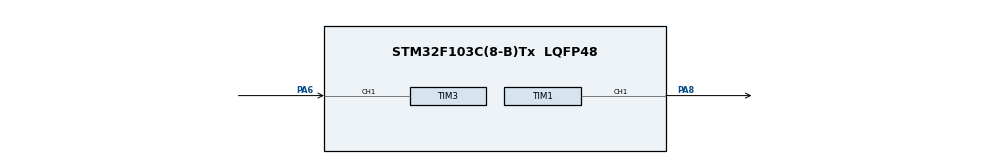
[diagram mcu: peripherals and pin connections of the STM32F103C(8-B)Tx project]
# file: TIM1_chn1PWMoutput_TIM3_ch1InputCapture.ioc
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Dma.Request0=TIM1_CH1
Dma.TIM1_CH1.0.Direction=DMA_MEMORY_TO_PERIPH
Dma.TIM1_CH1.0.Instance=DMA1_Channel2
Dma.TIM1_CH1.0.MemDataAlignment=DMA_MDATAALIGN_WORD
Dma.TIM1_CH1.0.MemInc=DMA_MINC_ENABLE
Dma.TIM1_CH1.0.Mode=DMA_CIRCULAR
Dma.TIM1_CH1.0.PeriphDataAlignment=DMA_PDATAALIGN_HALFWORD
Dma.TIM1_CH1.0.PeriphInc=DMA_PINC_DISABLE
Dma.TIM1_CH1.0.Priority=DMA_PRIORITY_HIGH
Mcu.Family=STM32F1
Mcu.Name=STM32F103C(8-B)Tx
Mcu.Package=LQFP48
NVIC.DMA1_Channel2_IRQn=true\:0\:0\:false\:false\:true
NVIC.PriorityGroup=NVIC_PRIORITYGROUP_4
NVIC.TIM3_IRQn=true\:0\:0\:false\:false\:true
PA6.GPIO_PuPd=GPIO_NOPULL
PA6.Signal=S_TIM3_CH1
PA8.GPIO_Speed=GPIO_SPEED_FREQ_HIGH
PA8.Signal=S_TIM1_CH1
PD0-OSC_IN.Mode=HSE-External-Oscillator
PD0-OSC_IN.Signal=RCC_OSC_IN
PD1-OSC_OUT.Mode=HSE-External-Oscillator
PD1-OSC_OUT.Signal=RCC_OSC_OUT
ProjectManager.HeapSize=0x200
ProjectManager.StackSize=0x400
ProjectManager.TargetToolchain=SW4STM32
RCC.APB1Freq_Value=8000000
RCC.APB2Freq_Value=8000000
SH.S_TIM1_CH1.0=TIM1_CH1,PWM Generation1 CH1
SH.S_TIM3_CH1.0=TIM3_CH1,Input_Capture1_from_TI1
TIM1.Channel-PWM\ Generation1\ CH1=TIM_CHANNEL_1
TIM1.TIM_MasterOutputTrigger=TIM_TRGO_OC1
TIM3.Channel-Input_Capture1_from_TI1=TIM_CHANNEL_1
TIM3.ICFilter_CH1=0
TIM3.Period=0
VP_TIM3_VS_ClockSourceINT.Mode=Internal
board=TIM1_chn1PWMoutput_TIM3_ch1InputCapture

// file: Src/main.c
/**
  ******************************************************************************
  * File Name          : main.c
  * Description        : Main program body
  ******************************************************************************
  ** This notice applies to any and all portions of this file
  * that are not between comment pairs USER CODE BEGIN and
  * USER CODE END. Other portions of this file, whether
  * inserted by the user or by software development tools
  * are owned by their respective copyright owners.
  *
  * COPYRIGHT(c) 2017 STMicroelectronics
  *
  * Redistribution and use in source and binary forms, with or without modification,
  * are permitted provided that the following conditions are met:
  *   1. Redistributions of source code must retain the above copyright notice,
  *      this list of conditions and the following disclaimer.
  *   2. Redistributions in binary form must reproduce the above copyright notice,
  *      this list of conditions and the following disclaimer in the documentation
  *      and/or other materials provided with the distribution.
  *   3. Neither the name of STMicroelectronics nor the names of its contributors
  *      may be used to endorse or promote products derived from this software
  *      without specific prior written permission.
  *
  * THIS SOFTWARE IS PROVIDED BY THE COPYRIGHT HOLDERS AND CONTRIBUTORS "AS IS"
  * AND ANY EXPRESS OR IMPLIED WARRANTIES, INCLUDING, BUT NOT LIMITED TO, THE
  * IMPLIED WARRANTIES OF MERCHANTABILITY AND FITNESS FOR A PARTICULAR PURPOSE ARE
  * DISCLAIMED. IN NO EVENT SHALL THE COPYRIGHT HOLDER OR CONTRIBUTORS BE LIABLE
  * FOR ANY DIRECT, INDIRECT, INCIDENTAL, SPECIAL, EXEMPLARY, OR CONSEQUENTIAL
  * DAMAGES (INCLUDING, BUT NOT LIMITED TO, PROCUREMENT OF SUBSTITUTE GOODS OR
  * SERVICES; LOSS OF USE, DATA, OR PROFITS; OR BUSINESS INTERRUPTION) HOWEVER
  * CAUSED AND ON ANY THEORY OF LIABILITY, WHETHER IN CONTRACT, STRICT LIABILITY,
  * OR TORT (INCLUDING NEGLIGENCE OR OTHERWISE) ARISING IN ANY WAY OUT OF THE USE
  * OF THIS SOFTWARE, EVEN IF ADVISED OF THE POSSIBILITY OF SUCH DAMAGE.
  *
  ******************************************************************************
  */
#include "main.h"
#include "stm32f1xx_hal.h"

TIM_HandleTypeDef htim1;
TIM_HandleTypeDef htim3;
DMA_HandleTypeDef hdma_tim1_ch1;

/* USER CODE BEGIN PV */
/* Private variables ---------------------------------------------------------*/
/* Timer handler declaration */
TIM_HandleTypeDef TimHandle;

/* Timer Output Compare Configuration Structure declaration */
TIM_OC_InitTypeDef sConfig;

/* Capture Compare buffer */
uint32_t aCCValue_Buffer[3] = { 0, 0, 0 };

/* Timer Period*/
uint32_t uhTimerPeriod = 0;

/* Timer Input Capture Configuration Structure declaration */
TIM_IC_InitTypeDef sICConfig;

/* Captured Values */
uint32_t uwIC2Value1 = 0;
uint32_t uwIC2Value2 = 0;
uint32_t uwDiffCapture = 0;

/* Capture index */
uint16_t uhCaptureIndex = 0;

/* Frequency Value */
uint32_t uwFrequency = 0;

/* USER CODE END PV */

void SystemClock_Config(void);
static void MX_GPIO_Init(void);
static void MX_DMA_Init(void);
static void MX_TIM3_Init(void);
static void MX_TIM1_Init(void);
void HAL_TIM_MspPostInit(TIM_HandleTypeDef *htim);

/* USER CODE BEGIN PFP */
/* Private function prototypes -----------------------------------------------*/

/* USER CODE END PFP */

/* USER CODE BEGIN 0 */
void HAL_TIM_IC_CaptureCallback(TIM_HandleTypeDef *htim)
{
  if (htim->Channel == HAL_TIM_ACTIVE_CHANNEL_1)
  {
    if(uhCaptureIndex == 0)
    {
      /* Get the 1st Input Capture value */
      uwIC2Value1 = HAL_TIM_ReadCapturedValue(htim, TIM_CHANNEL_1);
      uhCaptureIndex = 1;
    }
    else if(uhCaptureIndex == 1)
    {
      /* Get the 2nd Input Capture value */
      uwIC2Value2 = HAL_TIM_ReadCapturedValue(htim, TIM_CHANNEL_1);

      /* Capture computation */
      if (uwIC2Value2 > uwIC2Value1)
      {
        uwDiffCapture = (uwIC2Value2 - uwIC2Value1);
      }
      else  /* (uwIC2Value2 <= uwIC2Value1) */
      {
        uwDiffCapture = ((0xFFFF - uwIC2Value1) + uwIC2Value2);
      }

      /* Frequency computation: for this example TIMx (TIM1) is clocked by
         2xAPB2Clk */
      uwFrequency = (2*HAL_RCC_GetPCLK2Freq()) / uwDiffCapture;
      uhCaptureIndex = 0;
    }
  }
}
/* USER CODE END 0 */

int main(void)
{

  /* MCU Configuration----------------------------------------------------------*/

  /* Reset of all peripherals, Initializes the Flash interface and the Systick. */
  HAL_Init();

  /* Configure the system clock */
  SystemClock_Config();

  /* Initialize all configured peripherals */
  MX_GPIO_Init();
  MX_DMA_Init();
  MX_TIM3_Init();
  MX_TIM1_Init();

  /* USER CODE BEGIN 2 */
	uhTimerPeriod = (uint32_t) ((SystemCoreClock / 10000) - 1);
	aCCValue_Buffer[0] =
			(uint32_t) (((uint32_t) 25 * (uhTimerPeriod - 1)) / 100);
	aCCValue_Buffer[1] =
			(uint32_t) (((uint32_t) 25 * (uhTimerPeriod - 1)) / 100);
	aCCValue_Buffer[2] =
			(uint32_t) (((uint32_t) 25 * (uhTimerPeriod - 1)) / 100);

	TimHandle.Instance = TIM1;
	TimHandle.Init.Period = uhTimerPeriod;
	TimHandle.Init.RepetitionCounter = 3;
	TimHandle.Init.Prescaler = 0;
	TimHandle.Init.ClockDivision = 0;
	TimHandle.Init.CounterMode = TIM_COUNTERMODE_UP;
	if (HAL_TIM_PWM_Init(&TimHandle) != HAL_OK) {
		/* Initialization Error */
		Error_Handler();
	}

	/*##-2- Configure the PWM channel 3 ########################################*/
	sConfig.OCMode = TIM_OCMODE_PWM1;
	sConfig.OCPolarity = TIM_OCPOLARITY_HIGH;
	sConfig.Pulse = aCCValue_Buffer[0];
	if (HAL_TIM_PWM_ConfigChannel(&TimHandle, &sConfig, TIM_CHANNEL_1)
			!= HAL_OK) {
		/* Configuration Error */
		Error_Handler();
	}

	/*##-3- Start PWM signal generation in DMA mode ############################*/
	if (HAL_TIM_PWM_Start_DMA(&TimHandle, TIM_CHANNEL_1, aCCValue_Buffer, 3)
			!= HAL_OK) {
		/* Starting PWM generation Error */
		Error_Handler();
	}
	TimHandle.Instance = TIM3;

	TimHandle.Init.Period = 0xFFFF;
	TimHandle.Init.Prescaler = 0;
	TimHandle.Init.ClockDivision = 0;
	TimHandle.Init.CounterMode = TIM_COUNTERMODE_UP;
	if (HAL_TIM_IC_Init(&TimHandle) != HAL_OK) {
		/* Initialization Error */
		Error_Handler();
	}

	sICConfig.ICPolarity = TIM_ICPOLARITY_RISING;
	sICConfig.ICSelection = TIM_ICSELECTION_DIRECTTI;
	sICConfig.ICPrescaler = TIM_ICPSC_DIV1;
	sICConfig.ICFilter = 0;
	if (HAL_TIM_IC_ConfigChannel(&TimHandle, &sICConfig, TIM_CHANNEL_1)
			!= HAL_OK) {
		/* Configuration Error */
		Error_Handler();
	}

	/*##-3- Start the Input Capture in interrupt mode ##########################*/
	if (HAL_TIM_IC_Start_IT(&TimHandle, TIM_CHANNEL_1) != HAL_OK) {
		/* Starting Error */
		Error_Handler();
	}
  /* USER CODE END 2 */
	int count = 0;
  /* Infinite loop */
	while (1) {

  /* USER CODE BEGIN 3 */
		if(count != 0)
			count  = 0;
		else
			count = 1;
	}
  /* USER CODE END 3 */

}

/** System Clock Configuration
*/
void SystemClock_Config(void)
{

  RCC_OscInitTypeDef RCC_OscInitStruct;
  RCC_ClkInitTypeDef RCC_ClkInitStruct;

    /**Initializes the CPU, AHB and APB busses clocks
    */
  RCC_OscInitStruct.OscillatorType = RCC_OSCILLATORTYPE_HSI;
  RCC_OscInitStruct.HSIState = RCC_HSI_ON;
  RCC_OscInitStruct.HSICalibrationValue = 16;
  RCC_OscInitStruct.PLL.PLLState = RCC_PLL_NONE;
  if (HAL_RCC_OscConfig(&RCC_OscInitStruct) != HAL_OK)
  {
    _Error_Handler(__FILE__, __LINE__);
  }

    /**Initializes the CPU, AHB and APB busses clocks
    */
  RCC_ClkInitStruct.ClockType = RCC_CLOCKTYPE_HCLK|RCC_CLOCKTYPE_SYSCLK
                              |RCC_CLOCKTYPE_PCLK1|RCC_CLOCKTYPE_PCLK2;
  RCC_ClkInitStruct.SYSCLKSource = RCC_SYSCLKSOURCE_HSI;
  RCC_ClkInitStruct.AHBCLKDivider = RCC_SYSCLK_DIV1;
  RCC_ClkInitStruct.APB1CLKDivider = RCC_HCLK_DIV1;
  RCC_ClkInitStruct.APB2CLKDivider = RCC_HCLK_DIV1;

  if (HAL_RCC_ClockConfig(&RCC_ClkInitStruct, FLASH_LATENCY_0) != HAL_OK)
  {
    _Error_Handler(__FILE__, __LINE__);
  }

    /**Configure the Systick interrupt time
    */
  HAL_SYSTICK_Config(HAL_RCC_GetHCLKFreq()/1000);

    /**Configure the Systick
    */
  HAL_SYSTICK_CLKSourceConfig(SYSTICK_CLKSOURCE_HCLK);

  /* SysTick_IRQn interrupt configuration */
  HAL_NVIC_SetPriority(SysTick_IRQn, 0, 0);
}

/* TIM1 init function */
static void MX_TIM1_Init(void)
{

  TIM_MasterConfigTypeDef sMasterConfig;
  TIM_OC_InitTypeDef sConfigOC;
  TIM_BreakDeadTimeConfigTypeDef sBreakDeadTimeConfig;

  htim1.Instance = TIM1;
  htim1.Init.Prescaler = 0;
  htim1.Init.CounterMode = TIM_COUNTERMODE_UP;
  htim1.Init.Period = 0;
  htim1.Init.ClockDivision = TIM_CLOCKDIVISION_DIV1;
  htim1.Init.RepetitionCounter = 0;
  if (HAL_TIM_PWM_Init(&htim1) != HAL_OK)
  {
    _Error_Handler(__FILE__, __LINE__);
  }

  sMasterConfig.MasterOutputTrigger = TIM_TRGO_OC1;
  sMasterConfig.MasterSlaveMode = TIM_MASTERSLAVEMODE_DISABLE;
  if (HAL_TIMEx_MasterConfigSynchronization(&htim1, &sMasterConfig) != HAL_OK)
  {
    _Error_Handler(__FILE__, __LINE__);
  }

  sConfigOC.OCMode = TIM_OCMODE_PWM1;
  sConfigOC.Pulse = 0;
  sConfigOC.OCPolarity = TIM_OCPOLARITY_HIGH;
  sConfigOC.OCNPolarity = TIM_OCNPOLARITY_HIGH;
  sConfigOC.OCFastMode = TIM_OCFAST_DISABLE;
  sConfigOC.OCIdleState = TIM_OCIDLESTATE_RESET;
  sConfigOC.OCNIdleState = TIM_OCNIDLESTATE_RESET;
  if (HAL_TIM_PWM_ConfigChannel(&htim1, &sConfigOC, TIM_CHANNEL_1) != HAL_OK)
  {
    _Error_Handler(__FILE__, __LINE__);
  }

  sBreakDeadTimeConfig.OffStateRunMode = TIM_OSSR_DISABLE;
  sBreakDeadTimeConfig.OffStateIDLEMode = TIM_OSSI_DISABLE;
  sBreakDeadTimeConfig.LockLevel = TIM_LOCKLEVEL_OFF;
  sBreakDeadTimeConfig.DeadTime = 0;
  sBreakDeadTimeConfig.BreakState = TIM_BREAK_DISABLE;
  sBreakDeadTimeConfig.BreakPolarity = TIM_BREAKPOLARITY_HIGH;
  sBreakDeadTimeConfig.AutomaticOutput = TIM_AUTOMATICOUTPUT_DISABLE;
  if (HAL_TIMEx_ConfigBreakDeadTime(&htim1, &sBreakDeadTimeConfig) != HAL_OK)
  {
    _Error_Handler(__FILE__, __LINE__);
  }

  HAL_TIM_MspPostInit(&htim1);

}

/* TIM3 init function */
static void MX_TIM3_Init(void)
{

  TIM_ClockConfigTypeDef sClockSourceConfig;
  TIM_MasterConfigTypeDef sMasterConfig;
  TIM_IC_InitTypeDef sConfigIC;

  htim3.Instance = TIM3;
  htim3.Init.Prescaler = 0;
  htim3.Init.CounterMode = TIM_COUNTERMODE_UP;
  htim3.Init.Period = 0;
  htim3.Init.ClockDivision = TIM_CLOCKDIVISION_DIV1;
  if (HAL_TIM_Base_Init(&htim3) != HAL_OK)
  {
    _Error_Handler(__FILE__, __LINE__);
  }

  sClockSourceConfig.ClockSource = TIM_CLOCKSOURCE_INTERNAL;
  if (HAL_TIM_ConfigClockSource(&htim3, &sClockSourceConfig) != HAL_OK)
  {
    _Error_Handler(__FILE__, __LINE__);
  }

  if (HAL_TIM_IC_Init(&htim3) != HAL_OK)
  {
    _Error_Handler(__FILE__, __LINE__);
  }

  sMasterConfig.MasterOutputTrigger = TIM_TRGO_RESET;
  sMasterConfig.MasterSlaveMode = TIM_MASTERSLAVEMODE_DISABLE;
  if (HAL_TIMEx_MasterConfigSynchronization(&htim3, &sMasterConfig) != HAL_OK)
  {
    _Error_Handler(__FILE__, __LINE__);
  }

  sConfigIC.ICPolarity = TIM_INPUTCHANNELPOLARITY_RISING;
  sConfigIC.ICSelection = TIM_ICSELECTION_DIRECTTI;
  sConfigIC.ICPrescaler = TIM_ICPSC_DIV1;
  sConfigIC.ICFilter = 0;
  if (HAL_TIM_IC_ConfigChannel(&htim3, &sConfigIC, TIM_CHANNEL_1) != HAL_OK)
  {
    _Error_Handler(__FILE__, __LINE__);
  }

}

static void MX_DMA_Init(void)
{
  /* DMA controller clock enable */
  __HAL_RCC_DMA1_CLK_ENABLE();

  /* DMA interrupt init */
  /* DMA1_Channel2_IRQn interrupt configuration */
  HAL_NVIC_SetPriority(DMA1_Channel2_IRQn, 0, 0);
  HAL_NVIC_EnableIRQ(DMA1_Channel2_IRQn);

}

/** Configure pins as
        * Analog
        * Input
        * Output
        * EVENT_OUT
        * EXTI
*/
static void MX_GPIO_Init(void)
{

  /* GPIO Ports Clock Enable */
  __HAL_RCC_GPIOD_CLK_ENABLE();
  __HAL_RCC_GPIOA_CLK_ENABLE();

}

void _Error_Handler(char * file, int line)
{
	while (1) {
	}
}

/************************ (C) COPYRIGHT STMicroelectronics *****END OF FILE****/
